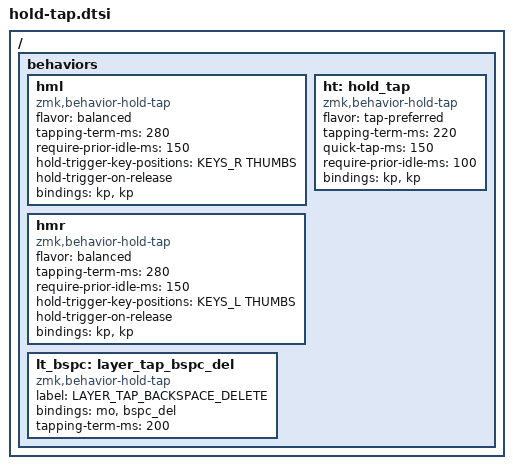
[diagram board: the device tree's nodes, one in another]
// Home Row Mods
#define KEYS_L LT0 LT1 LT2 LT3 LT4 LM0 LM1 LM2 LM3 LM4 LB0 LB1 LB2 LB3 LB4  // left-hand keys
#define KEYS_R RT0 RT1 RT2 RT3 RT4 RM0 RM1 RM2 RM3 RM4 RB0 RB1 RB2 RB3 RB4  // right-hand keys
#define THUMBS LH2 LH1 LH0 RH0 RH1 RH2 // thumb keys

// Home row mods macro
#define HRML(k1,k2,k3,k4) &hml LGUI k1  &hml LALT k2  &hml LCTRL k3  &hml LSHFT k4
#define HRMR(k1,k2,k3,k4) &hmr RSHFT k1  &hmr RCTRL k2  &hmr RALT k3  &hmr RGUI k4

// left-hand HRMs
ZMK_HOLD_TAP(hml,
    flavor = "balanced";
    tapping-term-ms = <280>;
    require-prior-idle-ms = <150>;
    hold-trigger-key-positions = <KEYS_R THUMBS>;
    hold-trigger-on-release;
    bindings = <&kp>, <&kp>;
)

ZMK_HOLD_TAP(hmr,
    flavor = "balanced";
    tapping-term-ms = <280>;
    require-prior-idle-ms = <150>;
    hold-trigger-key-positions = <KEYS_L THUMBS>;
    hold-trigger-on-release;
    bindings = <&kp>, <&kp>;
)


/ {
    behaviors {
        ht: hold_tap {
            compatible = "zmk,behavior-hold-tap";
            #binding-cells = <2>;
            flavor = "tap-preferred";
            tapping-term-ms = <220>;
            quick-tap-ms = <150>;
            require-prior-idle-ms = <100>;
            bindings = <&kp>, <&kp>;
        };

        lt_bspc: layer_tap_bspc_del {
            compatible = "zmk,behavior-hold-tap";
            label = "LAYER_TAP_BACKSPACE_DELETE";
            #binding-cells = <2>;
            bindings = <&mo>, <&bspc_del>;
            tapping-term-ms = <200>;
        };
    };
};
